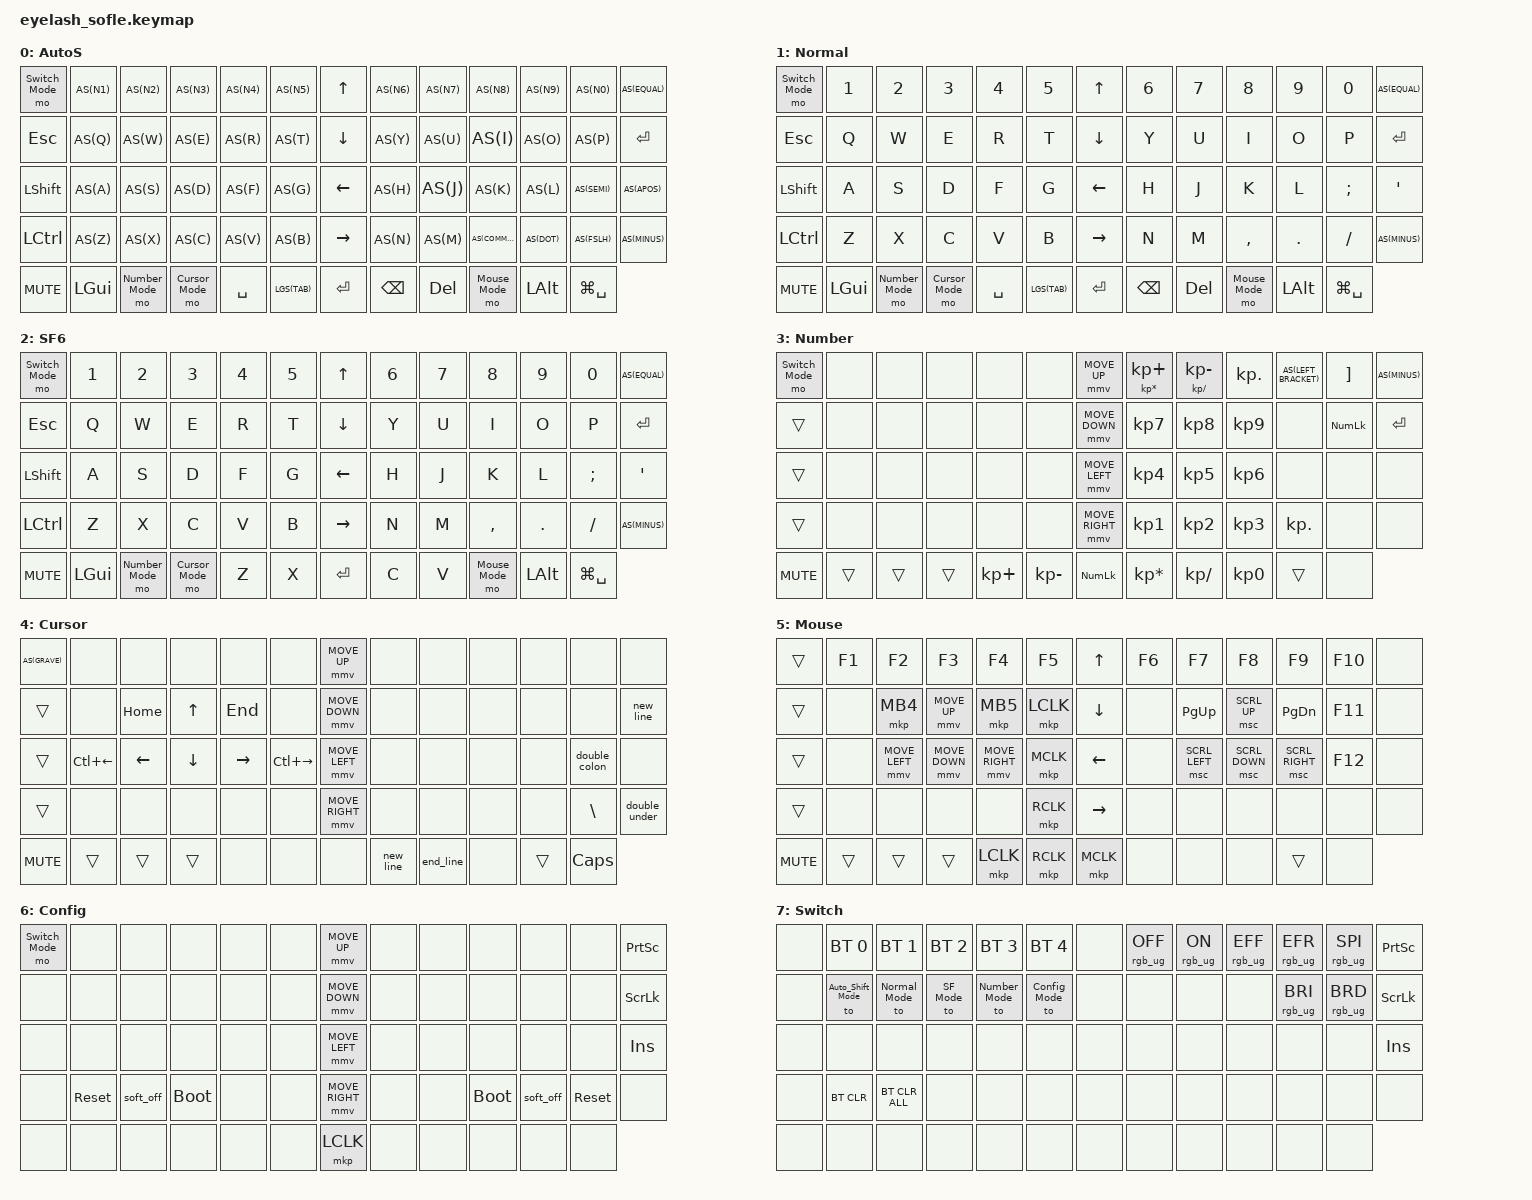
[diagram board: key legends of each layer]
#define ZMK_POINTING_DEFAULT_MOVE_VAL 1200  // 600
#define ZMK_POINTING_DEFAULT_SCRL_VAL 25   // 10

// Define layer nick name.
#define Auto_Shift_Mode 0
#define Normal_Mode 1
#define SF_Mode 2 
#define Number_Mode 3
#define Cursor_Mode 4
#define Mouse_Mode 5
#define Config_Mode 6
#define Switch_Mode 7

#define AS(keycode) &as LS(keycode) keycode
#define LGS(keycode) &as LG(keycode) keycode

#include <input/processors.dtsi>
#include <zephyr/dt-bindings/input/input-event-codes.h>
#include <behaviors.dtsi>
#include <dt-bindings/zmk/bt.h>
#include <dt-bindings/zmk/ext_power.h>
#include <dt-bindings/zmk/keys.h>
#include <dt-bindings/zmk/pointing.h>
#include <dt-bindings/zmk/rgb.h>
#include <dt-bindings/zmk/outputs.h>


&mmv_input_listener { input-processors = <&zip_xy_scaler 2 1>; };

&msc_input_listener { input-processors = <&zip_scroll_scaler 2 1>; };

&msc {
    acceleration-exponent = <1>;      // 0
    time-to-max-speed-ms = <100>;       // 300
    delay-ms = <0>;                   // 0
};

&mmv {
    time-to-max-speed-ms = <500>;
    acceleration-exponent = <1>;
    trigger-period-ms = <16>;
};


/ {
    behaviors {
        as: auto_shift {
            compatible = "zmk,behavior-hold-tap";
            #binding-cells = <2>;
            tapping-term-ms = <300>;
            quick-tap-ms = <300>;
            flavor = "tap-preferred";
            bindings = <&kp>, <&kp>;
        };
        scroll_up_down: scroll_up_down {
            compatible = "zmk,behavior-sensor-rotate";
            #sensor-binding-cells = <0>;
            bindings = <&msc SCRL_DOWN>, <&msc SCRL_UP>;
            tap-ms = <100>;
        };   
        scroll_left_right: scroll_left_right {
            compatible = "zmk,behavior-sensor-rotate";
            #sensor-binding-cells = <0>;
            bindings = <&msc SCRL_DOWN>, <&msc SCRL_UP>;
            tap-ms = <100>;
        };  

    };
    combos {
        compatible = "zmk,combos";

        combo_left_par {
            bindings = <&kp LEFT_PARENTHESIS>;
            key-positions = <2 3>;
            layers = <0 1>;
        };

        combo_right_par {
            bindings = <&kp RIGHT_PARENTHESIS>;
            key-positions = <9 10>;
            layers = <0 1>;
        };

        combo_left_brace {
            bindings = <&kp LEFT_BRACE>;
            key-positions = <4 5>;
            layers = <0 1>;
        };

        combo_right_brace {
            bindings = <&kp RIGHT_BRACE>;
            key-positions = <7 8>;
            layers = <0 1>;
        };

        combo_left_bkt {
            bindings = <&kp LEFT_BRACKET>;
            key-positions = <3 4>;
            layers = <0 1>;
        };

        combo_right_bkt {
            bindings = <&kp RIGHT_BRACKET>;
            key-positions = <8 9>;
            layers = <0 1>;
        };

        combo_bac {
            bindings = <&kp BACKSLASH>;
            key-positions = <18 20>;
            layers = <0 1>;
        };

        combo_pipe {
            bindings = <&kp PIPE>;
            key-positions = <31 33>;
            layers = <0 1>;
        };
    };
    macros {
        end_line: end_line {
            compatible = "zmk,behavior-macro";
            #binding-cells = <0>;
            bindings
                = <&macro_tap &kp END &kp COLON &kp ENTER>;
        };

        new_line: new_line {
            compatible = "zmk,behavior-macro";
            #binding-cells = <0>;
            bindings
                = <&macro_tap &kp END &kp ENTER>;
        };

        double_under: double_under {
            compatible = "zmk,behavior-macro";
            #binding-cells = <0>;
            bindings
                = <&macro_tap &kp UNDER &kp UNDER>;
        };

        double_colon: double_colon {
            compatible = "zmk,behavior-macro";
            #binding-cells = <0>;
            bindings
                = <&macro_tap &kp COLON &kp COLON>;
        };
    };

    keymap {
        compatible = "zmk,keymap";

        auto_s_layer {
            bindings = <
                &mo Switch_Mode    AS(N1)         AS(N2)             AS(N3)             AS(N4)        AS(N5)              &kp UP_ARROW         AS(N6)           AS(N7)        AS(N8)               AS(N9)              AS(N0)           AS(EQUAL)
                &kp ESC            AS(Q)          AS(W)              AS(E)              AS(R)         AS(T)               &kp DOWN_ARROW       AS(Y)            AS(U)         AS(I)                AS(O)               AS(P)            &kp ENTER
                &kp LSHFT          AS(A)          AS(S)              AS(D)              AS(F)         AS(G)               &kp LEFT_ARROW       AS(H)            AS(J)         AS(K)                AS(L)               AS(SEMI)         AS(APOS)
                &kp LCTRL          AS(Z)          AS(X)              AS(C)              AS(V)         AS(B)               &kp RIGHT_ARROW      AS(N)            AS(M)         AS(COMMA)            AS(DOT)             AS(FSLH)         AS(MINUS)
                &kp C_MUTE         &kp LEFT_GUI   &mo Number_Mode    &mo Cursor_Mode    &kp SPACE     LGS(TAB)            &kp ENTER            &kp BACKSPACE    &kp DEL       &mo Mouse_Mode       &kp LEFT_ALT        &kp LG(SPACE)
            >;
            sensor-bindings = <&inc_dec_kp C_VOLUME_UP C_VOL_DN>;
            display-name = "AutoS";
        };

        normal_layer {
            bindings = <
                &mo Switch_Mode   &kp N1        &kp N2            &kp N3                &kp N4        &kp N5            &kp UP_ARROW           &kp N6           &kp N7        &kp N8             &kp N9             &kp N0         AS(EQUAL)
                &kp ESC           &kp Q         &kp W             &kp E                 &kp R         &kp T             &kp DOWN_ARROW         &kp Y            &kp U         &kp I              &kp O              &kp P          &kp ENTER
                &kp LSHFT         &kp A         &kp S             &kp D                 &kp F         &kp G             &kp LEFT_ARROW         &kp H            &kp J         &kp K              &kp L              &kp SEMI       &kp APOS
                &kp LCTRL         &kp Z         &kp X             &kp C                 &kp V         &kp B             &kp RIGHT_ARROW        &kp N            &kp M         &kp COMMA          &kp DOT            &kp FSLH       AS(MINUS)
                &kp C_MUTE        &kp LEFT_GUI  &mo Number_Mode   &mo Cursor_Mode       &kp SPACE     LGS(TAB)          &kp ENTER              &kp BACKSPACE    &kp DEL       &mo Mouse_Mode     &kp LEFT_ALT       &kp LG(SPACE)
            >;
            sensor-bindings = <&inc_dec_kp C_VOLUME_UP C_VOL_DN>;
            display-name = "Normal";
        };

        game_layer {
            bindings = <
                &mo Switch_Mode   &kp N1        &kp N2            &kp N3                &kp N4        &kp N5            &kp UP_ARROW           &kp N6           &kp N7        &kp N8             &kp N9             &kp N0         AS(EQUAL)
                &kp ESC           &kp Q         &kp W             &kp E                 &kp R         &kp T             &kp DOWN_ARROW         &kp Y            &kp U         &kp I              &kp O              &kp P          &kp ENTER
                &kp LSHFT         &kp A         &kp S             &kp D                 &kp F         &kp G             &kp LEFT_ARROW         &kp H            &kp J         &kp K              &kp L              &kp SEMI       &kp APOS
                &kp LCTRL         &kp Z         &kp X             &kp C                 &kp V         &kp B             &kp RIGHT_ARROW        &kp N            &kp M         &kp COMMA          &kp DOT            &kp FSLH       AS(MINUS)
                &kp C_MUTE        &kp LEFT_GUI  &mo Number_Mode   &mo Cursor_Mode       &kp Z         &kp X             &kp ENTER              &kp C            &kp V         &mo Mouse_Mode     &kp LEFT_ALT       &kp LG(SPACE)
            >;
            sensor-bindings = <&inc_dec_kp C_VOLUME_UP C_VOL_DN>;
            display-name = "SF6";
        };

        number_layer {
            bindings = <
                &mo Switch_Mode   &none       &none       &none       &none            &none               &mmv MOVE_UP         &as KP_MULTIPLY KP_PLUS      &as KP_DIVIDE KP_MINUS      &kp KP_DOT      AS(LEFT_BRACKET)     &kp RIGHT_BRACKET      AS(MINUS)
                &trans            &none       &none       &none       &none            &none               &mmv MOVE_DOWN       &kp KP_N7                    &kp KP_N8                   &kp KP_N9       &none                &kp KP_NUM                  &kp ENTER
                &trans            &none       &none       &none       &none            &none               &mmv MOVE_LEFT       &kp KP_N4                    &kp KP_N5                   &kp KP_N6       &none                &none                  &none
                &trans            &none       &none       &none       &none            &none               &mmv MOVE_RIGHT      &kp KP_N1                    &kp KP_N2                   &kp KP_N3       &kp KP_DOT           &none                  &none
                &kp C_MUTE        &trans      &trans      &trans      &kp KP_PLUS      &kp KP_MINUS        &kp KP_NUM           &kp KP_MULTIPLY              &kp KP_DIVIDE               &kp KP_N0       &trans               &none
            >;
            display-name = "Number";
            sensor-bindings = <&scroll_up_down>;
        };

        cursor_layer {
            bindings = <
                AS(GRAVE)   &none                &none              &none             &none            &none               &mmv MOVE_UP         &none          &none             &none       &none       &none            &none
                &trans      &none                &kp HOME           &kp UP_ARROW      &kp END          &none               &mmv MOVE_DOWN       &none          &none             &none       &none       &none            &new_line
                &trans      &kp LC(LEFT_ARROW)   &kp LEFT_ARROW     &kp DOWN_ARROW    &kp RIGHT_ARROW  &kp LC(RIGHT_ARROW) &mmv MOVE_LEFT       &none          &none             &none       &none       &double_colon    &none
                &trans      &none                &none              &none             &none            &none               &mmv MOVE_RIGHT      &none          &none             &none       &none       &kp BSLH         &double_under
                &kp C_MUTE  &trans               &trans             &trans            &none            &none               &none                &new_line      &end_line         &none       &trans      &kp CAPS
            >;
            display-name = "Cursor";
            sensor-bindings = <&scroll_up_down>;
        };

        mouse_layer {
            bindings = <
                &trans      &kp F1         &kp F2             &kp F3            &kp F4           &kp F5            &kp UP_ARROW     &kp F6     &kp F7            &kp F8             &kp F9             &kp F10     &none
                &trans      &none          &mkp MB4           &mmv MOVE_UP      &mkp MB5         &mkp LCLK         &kp DOWN_ARROW   &none      &kp PAGE_UP       &msc SCRL_UP       &kp PAGE_DOWN      &kp F11     &none
                &trans      &none          &mmv MOVE_LEFT     &mmv MOVE_DOWN    &mmv MOVE_RIGHT  &mkp MCLK         &kp LEFT_ARROW   &none      &msc SCRL_LEFT    &msc SCRL_DOWN     &msc SCRL_RIGHT    &kp F12     &none
                &trans      &none          &none              &none             &none            &mkp RCLK         &kp RIGHT_ARROW  &none      &none             &none              &none              &none       &none
                &kp C_MUTE  &trans         &trans             &trans            &mkp LCLK        &mkp RCLK         &mkp MCLK        &none      &none             &none              &trans             &none
            >;   
            display-name = "Mouse";
            sensor-bindings = <&scroll_left_right>;
        };

        config_layer {
            bindings = <
                &mo Switch_Mode     &none         &none           &none         &none         &none          &mmv MOVE_UP         &none               &none              &none               &none                &none         &kp PRINTSCREEN
                &none               &none         &none           &none         &none         &none          &mmv MOVE_DOWN       &none               &none              &none               &none                &none         &kp SCROLLLOCK
                &none               &none         &none           &none         &none         &none          &mmv MOVE_LEFT       &none               &none              &none               &none                &none         &kp INSERT
                &none               &sys_reset    &soft_off       &bootloader   &none         &none          &mmv MOVE_RIGHT      &none               &none              &bootloader         &soft_off            &sys_reset    &none
                &none               &none         &none           &none         &none         &none          &mkp LCLK            &none               &none              &none               &none                &none
            >;
            display-name = "Config";
            sensor-bindings = <&scroll_up_down>;
        };

        switch_layer {
            bindings = <
                &none   &bt BT_SEL 0          &bt BT_SEL 1         &bt BT_SEL 2        &bt BT_SEL 3     &bt BT_SEL 4       &none               &rgb_ug RGB_OFF     &rgb_ug RGB_ON     &rgb_ug RGB_EFF     &rgb_ug RGB_EFR      &rgb_ug RGB_SPI     &kp PRINTSCREEN
                &none   &to Auto_Shift_Mode   &to Normal_Mode      &to SF_Mode  &to Number_Mode  &to Config_Mode    &none               &none               &none              &none               &rgb_ug RGB_BRI      &rgb_ug RGB_BRD     &kp SCROLLLOCK
                &none   &none                 &none                &none               &none            &none              &none               &none               &none              &none               &none                &none               &kp INSERT
                &none   &bt BT_CLR            &bt BT_CLR_ALL       &none               &none            &none              &none               &none               &none              &none               &none                &none               &none 
                &none   &none                 &none                &none               &none            &none              &none               &none               &none              &none               &none                &none
            >;
            sensor-bindings = <&inc_dec_kp C_VOLUME_UP C_VOL_DN>;
            display-name = "Switch";
        };
    };
};
